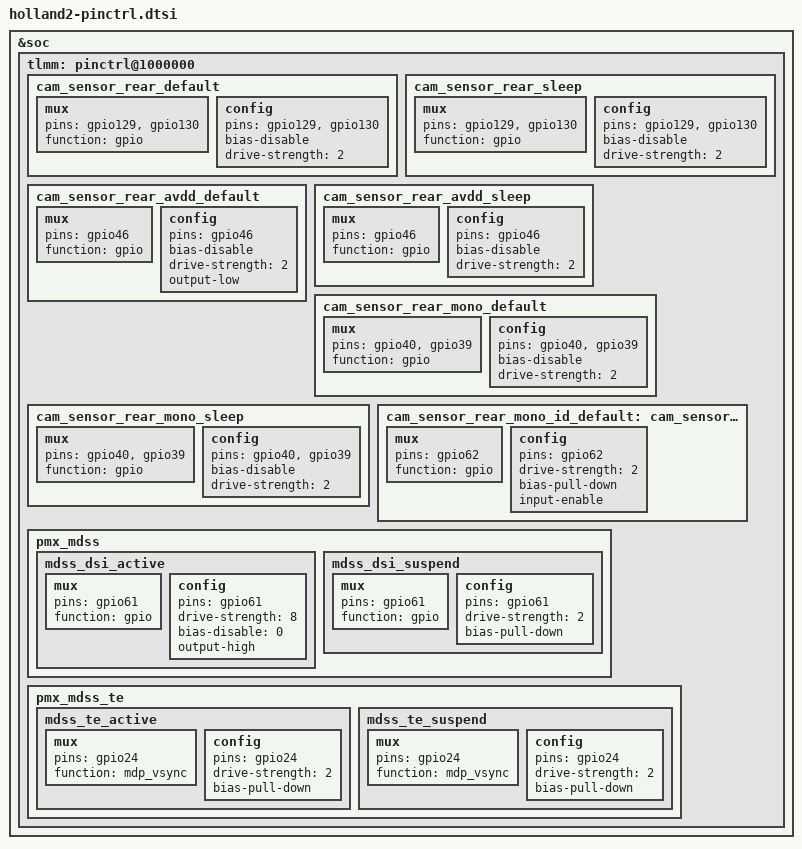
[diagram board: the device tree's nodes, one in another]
/* Copyright (c) 2020, The Linux Foundation. All rights reserved.
*  Copyright (c) 2020, Jebaitedneko.
*
* This program is free software; you can redistribute it and/or modify
* it under the terms of the GNU General Public License version 2 and
* only version 2 as published by the Free Software Foundation.
*
* This program is distributed in the hope that it will be useful,
* but WITHOUT ANY WARRANTY; without even the implied warranty of
* MERCHANTABILITY or FITNESS FOR A PARTICULAR PURPOSE.  See the
* GNU General Public License for more details.
*/

&soc {

	tlmm: pinctrl@1000000 {

		cam_sensor_rear_default: cam_sensor_rear_default {
			/* RESET, STANDBY */
			mux {
				pins = "gpio129", "gpio130";
				function = "gpio";
			};

			config {
				pins = "gpio129","gpio130";
				bias-disable; /* No PULL */
				drive-strength = <2>; /* 2 MA */
			};
		};

		cam_sensor_rear_sleep: cam_sensor_rear_sleep {
			/* RESET, STANDBY */
			mux {
				pins = "gpio129","gpio130";
				function = "gpio";
			};

			config {
				pins = "gpio129","gpio130";
				bias-disable; /* No PULL */
				drive-strength = <2>; /* 2 MA */
			};
		};

		cam_sensor_rear_avdd_default: cam_sensor_rear_avdd_default {
			/* AVDD */
			mux {
				pins = "gpio46";
				function = "gpio";
			};

			config {
				pins = "gpio46";
				bias-disable; /* No PULL */
				drive-strength = <2>; /* 2 MA */
				output-low;
			};
		};

		cam_sensor_rear_avdd_sleep: cam_sensor_rear_avdd_sleep {
			/* AVDD */
			mux {
				pins = "gpio46";
				function = "gpio";
			};

			config {
				pins = "gpio46";
				bias-disable; /* No PULL */
				drive-strength = <2>; /* 2 MA */
			};
		};

		cam_sensor_rear_mono_default: cam_sensor_rear_mono_default {
			/* RESET, STANDBY */
			mux {
				pins = "gpio40", "gpio39";
				function = "gpio";
			};

			config {
				pins = "gpio40","gpio39";
				bias-disable; /* No PULL */
				drive-strength = <2>; /* 2 MA */
			};
		};

		cam_sensor_rear_mono_sleep: cam_sensor_rear_mono_sleep {
			/* RESET, STANDBY */
			mux {
				pins = "gpio40","gpio39";
				function = "gpio";
			};

			config {
				pins = "gpio40","gpio39";
				bias-disable; /* No PULL */
				drive-strength = <2>; /* 2 MA */
			};
		};

		cam_sensor_rear_mono_id_default: cam_sensor_rear_mono_id {

			mux {
				pins = "gpio62";
				function = "gpio";
			};

			config {
				pins = "gpio62";
				drive-strength = <2>; /* 2 mA */
				bias-pull-down; /* pull down */
				input-enable;
			};
		};

		pmx_mdss: pmx_mdss {

			mdss_dsi_active: mdss_dsi_active {

				mux {
					pins = "gpio61";
					function = "gpio";
				};

				config {
					pins = "gpio61";
					drive-strength = <8>; /* 8 mA */
					bias-disable = <0>; /* no pull */
					output-high;
				};
			};

			mdss_dsi_suspend: mdss_dsi_suspend {

				mux {
					pins = "gpio61";
					function = "gpio";
				};

				config {
					pins = "gpio61";
					drive-strength = <2>; /* 2 mA */
					bias-pull-down; /* pull down */
				};
			};
		};

		pmx_mdss_te {

			mdss_te_active: mdss_te_active {

				mux {
					pins = "gpio24";
					function = "mdp_vsync";  //mdp_vsync
				};
				config {
					pins = "gpio24";
					drive-strength = <2>; /* 8 mA */
					bias-pull-down; /* pull down*/
				};
			};

			mdss_te_suspend: mdss_te_suspend {

				mux {
					pins = "gpio24";
					function = "mdp_vsync";  //mdp_vsync
				};
				config {
					pins = "gpio24";
					drive-strength = <2>; /* 2 mA */
					bias-pull-down; /* pull down */
				};
			};
		};
	};
};
